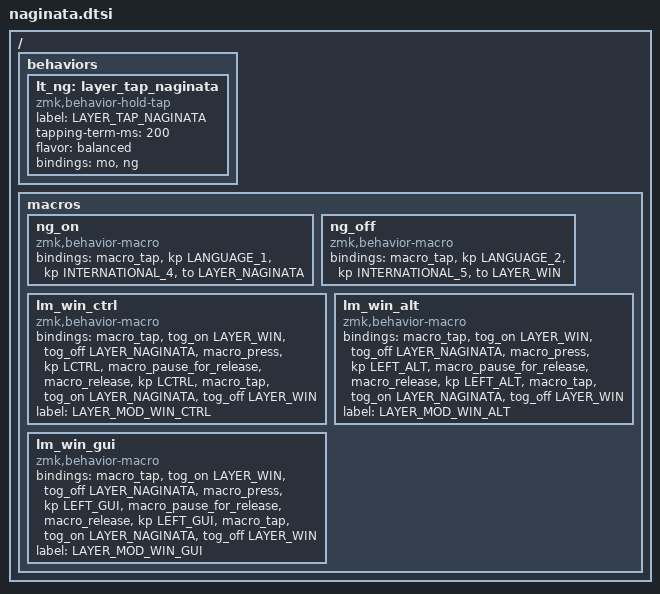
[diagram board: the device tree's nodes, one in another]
/*
 * 薙刀式 (Naginata) 関連の定義 (マクロ、ビヘイビア、コンボ)
 */
#pragma once

#include <behaviors/naginata.dtsi>

// 薙刀式用ビヘイビア (レイヤータップ + 薙刀キー)
/ {
    behaviors {
        lt_ng: layer_tap_naginata {
            compatible = "zmk,behavior-hold-tap";
            label = "LAYER_TAP_NAGINATA";
            #binding-cells = <2>;
            tapping-term-ms = <200>;
            flavor = "balanced";
            bindings = <&mo>, <&ng>;
        };
    };

    macros {
        ng_on: ng_on {
            compatible = "zmk,behavior-macro";
            #binding-cells = <0>;
            bindings
                = <&macro_tap &kp LANGUAGE_1 &kp INTERNATIONAL_4 &to LAYER_NAGINATA>
                ;
        };

        ng_off: ng_off {
            compatible = "zmk,behavior-macro";
            #binding-cells = <0>;
            bindings
                = <&macro_tap &kp LANGUAGE_2 &kp INTERNATIONAL_5 &to LAYER_WIN>
                ;
        };

        // Change only the typing layer; keep number/function layers active.
        lm_win_ctrl: lm_win_ctrl {
            compatible = "zmk,behavior-macro";
            #binding-cells = <0>;
            bindings
                = <&macro_tap &tog_on LAYER_WIN &tog_off LAYER_NAGINATA>
                , <&macro_press &kp LCTRL>
                , <&macro_pause_for_release>
                , <&macro_release &kp LCTRL>
                , <&macro_tap &tog_on LAYER_NAGINATA &tog_off LAYER_WIN>;
            label = "LAYER_MOD_WIN_CTRL";
        };

        lm_win_alt: lm_win_alt {
            compatible = "zmk,behavior-macro";
            #binding-cells = <0>;
            bindings
                = <&macro_tap &tog_on LAYER_WIN &tog_off LAYER_NAGINATA>
                , <&macro_press &kp LEFT_ALT>
                , <&macro_pause_for_release>
                , <&macro_release &kp LEFT_ALT>
                , <&macro_tap &tog_on LAYER_NAGINATA &tog_off LAYER_WIN>;
            label = "LAYER_MOD_WIN_ALT";
        };

        lm_win_gui: lm_win_gui {
            compatible = "zmk,behavior-macro";
            #binding-cells = <0>;
            bindings
                = <&macro_tap &tog_on LAYER_WIN &tog_off LAYER_NAGINATA>
                , <&macro_press &kp LEFT_GUI>
                , <&macro_pause_for_release>
                , <&macro_release &kp LEFT_GUI>
                , <&macro_tap &tog_on LAYER_NAGINATA &tog_off LAYER_WIN>;
            label = "LAYER_MOD_WIN_GUI";
        };
    };
};
